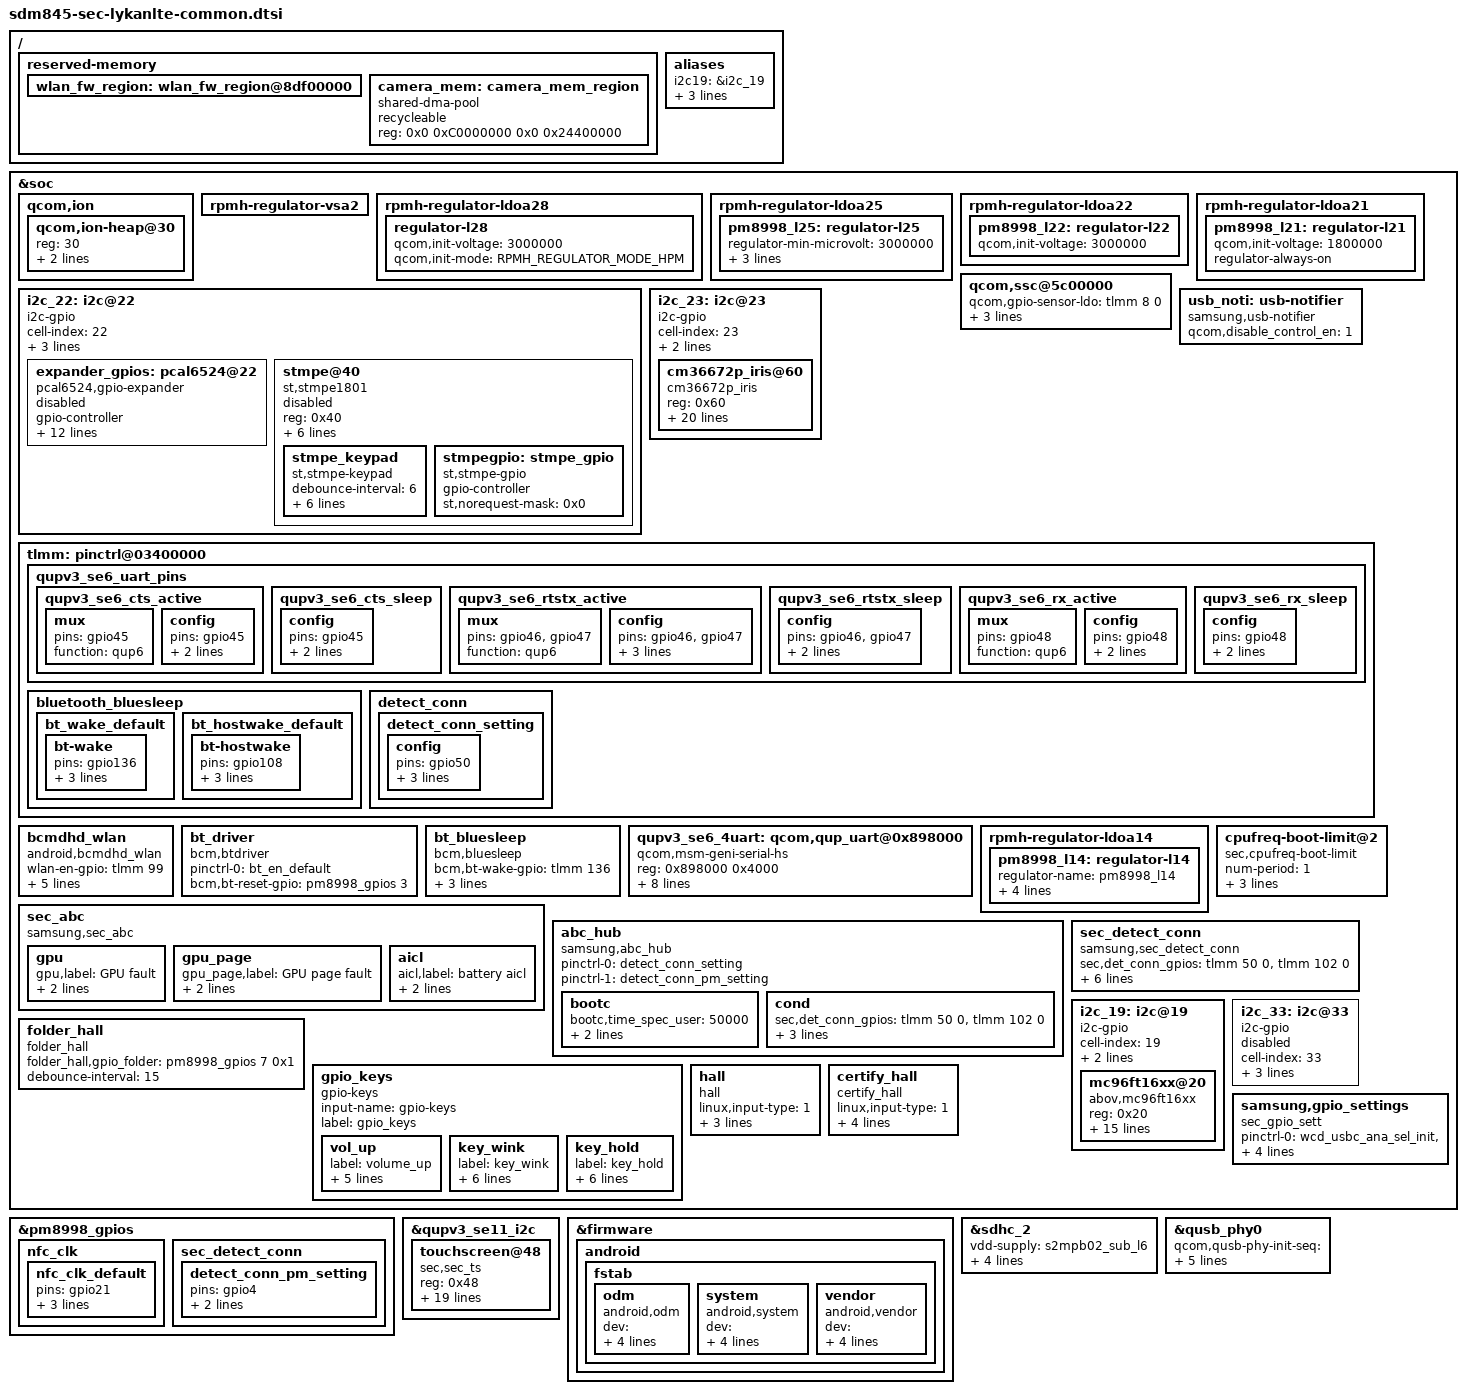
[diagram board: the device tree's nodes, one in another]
/* Copyright (c) 2016-2017, The Linux Foundation. All rights reserved.
 *
 * This program is free software; you can redistribute it and/or modify
 * it under the terms of the GNU General Public License version 2 and
 * only version 2 as published by the Free Software Foundation.
 *
 * This program is distributed in the hope that it will be useful,
 * but WITHOUT ANY WARRANTY; without even the implied warranty of
 * MERCHANTABILITY or FITNESS FOR A PARTICULAR PURPOSE.  See the
 * GNU General Public License for more details.
 */

#include "sdm845-sec-lykan-audio.dtsi"
#include "../../../../drivers/motor/tuning/star2qlte_motor_tuning.dtsi"
#include "../../../../drivers/leds/tuning/star2qlte_led_tuning.dtsi"
#include <dt-bindings/input/input.h>

/{
	reserved-memory {
		/*
		 * We need this region only if we use Qualcomm WiFi solution,
		 * otherwise no need.
		 */
		wlan_fw_region: wlan_fw_region@8df00000 {
			/delete-property/ reg;
		};

		camera_mem: camera_mem_region {
			compatible = "shared-dma-pool";
			recycleable;
			reg = <0x0 0xC0000000 0x0 0x24400000>;
		};
	};

	aliases {
		i2c19 = &i2c_19;
		i2c22 = &i2c_22;
		i2c33 = &i2c_33;
		spi2 = &qupv3_se2_spi;
	};

};

&soc {
	qcom,ion {
		qcom,ion-heap@30 { /* CAMERA HEAP  */
			reg = <30>;
			memory-region = <&camera_mem>;
			qcom,ion-heap-type = "RBIN";
		};
	};

	rpmh-regulator-vsa2 {
	};
	rpmh-regulator-ldoa28 {
		regulator-l28 {
			qcom,init-voltage = <3000000>;
			qcom,init-mode = <RPMH_REGULATOR_MODE_HPM>;
		};
	};
	
	rpmh-regulator-ldoa25 {
		pm8998_l25: regulator-l25 {
			regulator-min-microvolt = <3000000>;
			regulator-max-microvolt = <3312000>;
			qcom,init-voltage = <3000000>;
			qcom,init-mode = <RPMH_REGULATOR_MODE_LPM>;
			/delete-property/regulator-always-on;
		};
	};

	rpmh-regulator-ldoa22 {
		pm8998_l22: regulator-l22 {
			qcom,init-voltage = <3000000>;
		};
	};

	rpmh-regulator-ldoa21 {
		pm8998_l21: regulator-l21 {
			qcom,init-voltage = <1800000>;
			regulator-always-on;
		};
	};

	/* sensor ldo control gpio */
	qcom,ssc@5c00000 {
		/* GPIO control sensor LDO */
		qcom,gpio-sensor-ldo = <&tlmm 8 0>;
		pinctrl-names = "default", "sleep", "idle";
		pinctrl-0 = <&sensor_ldo_default>;
		pinctrl-1 = <&sensor_ldo_active>;
		pinctrl-2 = <&sensor_ldo_active>;
	};

	i2c_22: i2c@22 { /* pcal6524*/
		cell-index = <22>;
		compatible = "i2c-gpio";
		gpios = <&tlmm 123 0 /* sda */
			&tlmm 124 0 /* scl */
		>;
		i2c-gpio,delay-us = <2>;
		#address-cells = <1>;
		#size-cells = <0>;
		pinctrl-names = "default";
		pinctrl-0 = <&i2c_22_active>;

		expander_gpios: pcal6524@22 {
			compatible = "pcal6524,gpio-expander";
			status = "disabled";
			gpio-controller;
			#gpio-cells = <2>;
			reg = <0x22>;
			pinctrl-names = "expander_reset_setting";
			pinctrl-0 = <&expander_reset_active>;
			pcal6524,gpio_start = <300>;
			pcal6524,ngpio = <24>;
			pcal6524,reset-gpio = <&tlmm 69 0>;
			pcal6524,vdd-supply = <&pm8998_s4>;
			pcal6524,support_initialize = <1>;
			/* config, 24 ~ 0, 1bit configure[1:input, 0:output]*/
			pcal6524,config = <0x7FFFFF>;    /* P2[01111111] P1[11111111] P0[11111111] */
			/* data_out, 24 ~ 0, 1bit configure[1:high, 0:low]*/
			pcal6524,data_out = <0x000000>;  /* P2[00000000] P1[00000000] P0[00000000] */
			/* pull_reg, 8 ~ 0, 2bit configure[00:no_pull, 01:pull_down, 10:pull_up, 11:not used] */
			pcal6524,pull_reg_p0 = <0x0000>; /* 00 00 00 00 / 00 00 00 00 */
			pcal6524,pull_reg_p1 = <0x0000>; /* 00 00 00 00 / 00 00 00 00 */
			pcal6524,pull_reg_p2 = <0x0000>; /* 00 00 00 00 / 00 00 00 00 */
		};

		stmpe@40 {
			compatible = "st,stmpe1801";
			status = "disabled";
			reg = <0x40>;
			interrupt-parent = <&tlmm>;
			interrupts = <145 0>;
			irq-gpio = <&tlmm 145 0x08>;
			reset-gpio = <&tlmm 69 0x00>;
			vcc-supply = <&pm8998_s4>;
			//reset-supply = <&stmpe_reset>;
			ledvddo-supply = <&pm8998_l22>; 
								
			stmpe_keypad {
				compatible = "st,stmpe-keypad";

				debounce-interval = <6>;
				st,scan-count = <2>;
				st,no-autorepeat;
				keypad,num-rows = <5>;
				keypad,num-columns = <5>;	//  row   colume   keycode
				linux,keymap = <0x000000e7	/* KEY_SEND KEYCODE = 231 */
						0x0001000e	/* KEY_BACKSPACE 14 */
						0x00020224	/* KEY_NETWORK_SEL 548*/
						0x000300ac	/* KEY_HOMEPAGE 172*/
						0x00040161	/* KEY_ENTER 353 */

						0x01000002	/* KEY_1 2 */
						0x01010003	/* KEY_2 3 */
						0x01020004	/* KEY_3 4 */
						0x01030069	/* KEY_LEFT 105 */
						0x0104006c	/* KEY_DOWN 108 */

						0x02000005	/* KEY_4 5 */
						0x02010006	/* KEY_5 6 */
						0x02020007	/* KEY_6 7 */
						0x0203009e	/* KEY_BACK 158 */
						0x0204006a	/* KEY_RIGHT 106 */

						0x03000008	/* KEY_7 8 */
						0x03010009	/* KEY_8 9 */
						0x0302000a	/* KEY_9 10 */
						0x03030067	/* KEY_UP 103 */

						0x0400020a	/* KEY_NUMERIC_STAR 0x20a */
						0x0401000b	/* KEY_0 11 */
						0x0402020b	/* KEY_NUMERIC_POUND 0x20b */
						0x040300fe>;	/* KEY_RECENT 254 */				
				};

				stmpegpio:stmpe_gpio {
					compatible = "st,stmpe-gpio";
					gpio-controller;
					#gpio-cells = <2>;
					st,norequest-mask = <0x0>;
			};
		};
	};

	i2c_23: i2c@23 { /* SW I2C */
	        cell-index = <23>;
	        compatible = "i2c-gpio";
	        gpios = <&tlmm 91 0 /* sda */
	        	&tlmm 92 0 /* scl */
	        >;
	        i2c-gpio,delay-us = <2>;
	        #address-cells = <1>;
	        #size-cells = <0>;

	        cm36672p_iris@60 {
	            compatible = "cm36672p_iris";
	            reg = <0x60>;
	            pinctrl-names = "default", "sleep";
	            pinctrl-0 = <&cm36672p_int_active &cm36672p_i2c_active>;
	            pinctrl-1 = <&cm36672p_int_suspend &cm36672p_i2c_suspend>;
	            interrupt-parent = <&tlmm>;
	            interrupts = <122 0>;
	            cm36672p_iris,irq_gpio = <&tlmm 122 0x1>;
	            cm36672p_iris,vio-supply = <&pm8998_l21>;
	            cm36672p_iris,vdd-supply = <&s2mpb02_l16>;
	            cm36672p_iris,vled-supply = <&s2mpb02_l18>;
	            cm36672p_iris,default_hi_thd = <22>;
	            cm36672p_iris,default_low_thd = <2>;
	            cm36672p_iris,cancel_hi_thd = <8>;
	            cm36672p_iris,cancel_low_thd = <5>;
	            cm36672p_iris,default_trim = <20>;
	            cm36672p_iris,ps_duty = <2>;
	            cm36672p_iris,ps_pers = <2>;
	            cm36672p_iris,ps_it = <6>;
	            cm36672p_iris,led_current = <2>;
	            cm36672p_iris,ps_smart_pers = <1>;
		};
	};

	usb_noti: usb-notifier {
		compatible = "samsung,usb-notifier";
		qcom,disable_control_en = <1>;
	};
	tlmm: pinctrl@03400000 {
		/delete-node/ qupv3_se6_4uart_pins;
		qupv3_se6_uart_pins: qupv3_se6_uart_pins {
			qupv3_se6_cts_active: qupv3_se6_cts_active {
				mux {
					pins = "gpio45";
					function = "qup6";
				};
				config {
					pins = "gpio45";
					drive-strength = <2>;
					bias-pull-up;
				};
			};

			qupv3_se6_cts_sleep: qupv3_se6_cts_sleep {
				config {
					pins = "gpio45";
					drive-strength = <2>;
					bias-pull-up;
				};
			};

			qupv3_se6_rtstx_active: qupv3_se6_rtstx_active {
				mux {
					pins = "gpio46", "gpio47";
					function = "qup6";
				};
				config {
					pins = "gpio46","gpio47";
					drive-strength = <2>;
					output-high;
					bias-pull-up;
				};
			};

			qupv3_se6_rtstx_sleep: qupv3_se6_rtstx_sleep {
				config {
					pins = "gpio46","gpio47";
					drive-strength = <2>;
					bias-pull-up;
				};
			};

			qupv3_se6_rx_active: qupv3_se6_rx_active {
				mux {
					pins = "gpio48";
					function = "qup6";
				};
				config {
					pins = "gpio48";
					drive-strength = <2>;
					bias-pull-up;
				};
			};

			qupv3_se6_rx_sleep: qupv3_se6_rx_sleep {
				config {
					pins = "gpio48";
					drive-strength = <2>;
					bias-pull-up;
				};
			};
		};

		bluetooth_bluesleep {
			bt_wake_default: bt_wake_default {
				bt-wake {
					pins = "gpio136";
					function = "gpio";
					drive-strength = <2>;
					bias-pull-down;
				};
			};
			bt_hostwake_default: bt_hostwake_default {
				bt-hostwake {
					pins = "gpio108";
					function = "gpio";
					drive-strength = <2>;
					bias-pull-down;
				};
			};
		};
	};

	bcmdhd_wlan {
		compatible = "android,bcmdhd_wlan";
		wlan-en-gpio = <&tlmm 99 0>;
		wlan-host-wake-gpio = <&tlmm 116 0>;
		wlan-smmu-iova-address = <0xa0000000 0x10000000>;
		pinctrl-name = "bcmdhd_wlan_en","bcmdhd_default";
		pinctrl-0 = <&bcmdhd_wlan_en>;
		pinctrl-1 = <&bcmdhd_default>;
		status = "ok";
	};

	bt_driver {
		compatible = "bcm,btdriver";  //bt_en
		pinctrl-names = "default";
		pinctrl-0 = <&bt_en_default>;
		bcm,bt-reset-gpio = <&pm8998_gpios 3 GPIO_ACTIVE_HIGH>;
		status = "okay";
	};

	bt_bluesleep {
		compatible = "bcm,bluesleep";
		bcm,bt-wake-gpio = <&tlmm 136 0>;
		bcm,bt-host-wake-gpio = <&tlmm 108 0>;
		pinctrl-names = "default";
		pinctrl-0 = <&bt_wake_default &bt_hostwake_default>;
		status = "okay";
	};

	qupv3_se6_4uart: qcom,qup_uart@0x898000 {
		compatible = "qcom,msm-geni-serial-hs", "qcom,msm-geni-uart";
		reg = <0x898000 0x4000>;
		reg-names = "se_phys";
		clock-names = "se-clk", "m-ahb", "s-ahb";
		clocks = <&clock_gcc GCC_QUPV3_WRAP0_S6_CLK>,
			<&clock_gcc GCC_QUPV3_WRAP_0_M_AHB_CLK>,
			<&clock_gcc GCC_QUPV3_WRAP_0_S_AHB_CLK>;
		pinctrl-names = "default", "sleep";
		pinctrl-0 = <&qupv3_se6_cts_active &qupv3_se6_rtstx_active &qupv3_se6_rx_active>;
		pinctrl-1 = <&qupv3_se6_cts_sleep &qupv3_se6_rtstx_sleep &qupv3_se6_rx_sleep>;
		interrupts-extended = <&pdc GIC_SPI 607 0>;
		status = "okay";
	};

	rpmh-regulator-ldoa14 {
		pm8998_l14: regulator-l14 {
			regulator-name = "pm8998_l14";
			regulator-min-microvolt = <1800000>;
			regulator-max-microvolt = <1880000>;
			qcom,init-voltage = <1800000>;
			qcom,init-mode = <RPMH_REGULATOR_MODE_LPM>;
		};
	};

	cpufreq-boot-limit@2 {
		compatible = "sec,cpufreq-boot-limit";
		num-period = <1>;
		limit-temp = <(-70)>;
		limit-freq-table = <0 1536000 40000>;
		limit-for-user-bin;
		status = "ok";
	};

	sec_abc {
		compatible = "samsung,sec_abc";
		status = "okay";

		gpu {
			gpu,label="GPU fault";
			gpu,threshold_count=<4>;
			gpu,threshold_time=<1200>;
		};
		gpu_page {
			gpu_page,label="GPU page fault";
			gpu_page,threshold_count=<20>;
			gpu_page,threshold_time=<1200>;
		};
		aicl {
			aicl,label="battery aicl";
			aicl,threshold_count=<5>;
			aicl,threshold_time=<300>;
		};
	};

	abc_hub {
		compatible = "samsung,abc_hub";
		status = "okay";
		pinctrl-names = "det_ap_connect", "det_pm_connect";
		pinctrl-0 = <&detect_conn_setting>;
		pinctrl-1 = <&detect_conn_pm_setting>;
		
		bootc {
			bootc,time_spec_user = <50000>; /* user binary user build */
			bootc,time_spec_eng = <90000>; /* user binary eng build */
			bootc,time_spec_fac = <40000>; /* factory binary */
		};


		cond {
			sec,det_conn_gpios = <&tlmm 50 0 /* UB_CON_DETECT */
				&tlmm 102 0>; /* SUB_DETECT */
			
			sec,det_conn_name = "ub", "sub";
			sec,det_pm_conn_gpios = <&pm8998_gpios 4 0x1>; /* CAM_DETECT */
			sec,det_pm_conn_name = "cam";
		};
	};
	
	tlmm: pinctrl@03400000 {
		detect_conn {
			detect_conn_setting: detect_conn_setting {
				config {
					pins = "gpio50";
					drive-strength = <2>;
					bias-disable; /* No PULL */
					input-enable;
				};
			};
		};
	};
	
	sec_detect_conn {
		compatible = "samsung,sec_detect_conn";
		sec,det_conn_gpios = <&tlmm 50 0 /* UB_CON_DETECT */
					&tlmm 102 0>; /* SUB_DETECT */

		sec,det_conn_name = "UB_CONNECT", "SUB_CONNECT";

		sec,det_conn_irq_type = <3>, /* UB_CON_DETECT FALLING, RIGING EDGE*/
					<3>; /* SUB_DETECT FALLING, RIGING EDGE*/

		sec,det_pm_conn_gpios = <&pm8998_gpios 4 0x1>; /* CAM_DETECT */
		sec,det_pm_conn_name = "CAM_CONNECT";
		pinctrl-names = "det_ap_connect", "det_pm_connect";
		pinctrl-0 = <&detect_conn_setting>;
		pinctrl-1 = <&detect_conn_pm_setting>;
	};

	i2c_19: i2c@19 { /* SW I2C */
		cell-index = <19>;
		compatible = "i2c-gpio";
		gpios = <&tlmm 114 0 /* sda */
				&tlmm 115 0 /* scl */
		>;
		#i2c-gpio,delay-us = <2>;
		#address-cells = <1>;
		#size-cells = <0>;
		
		mc96ft16xx@20{
			compatible = "abov,mc96ft16xx";
			reg = <0x20>;
			interrupt-parent = <&tlmm>;
			interrupts = <79 0>;
			pinctrl-names = "touchkey_active", "touchkey_suspend";
			pinctrl-0 = <&touchkey_i2c_active &touchkey_int_active>;
			pinctrl-1 = <&touchkey_i2c_suspend &touchkey_int_suspend>;
			abov,avdd-supply = <&s2mpb02_sub_l17>;
			abov,vddo-supply = <&pm8998_s4>;
			abov,ledavdd-supply = <&s2mpb02_sub_l16>;
			abov,sda-gpio = <&tlmm 114 0x0>;
			abov,scl-gpio = <&tlmm 115 0x0>;
			abov,irq-gpio = <&tlmm 79 0x0>;
			abov,hall_flip-gpio = <&tlmm 96 0>;
			abov,reg-boot-on; /* enable supply when pmic boot on */
			abov,fw-name = "abov/abov_tk_kelly.fw";
		};
	};

	folder_hall {
		compatible = "folder_hall";
		folder_hall,gpio_folder = <&pm8998_gpios 7 0x1>;
		debounce-interval = <15>;
	};

	i2c_33: i2c@33 {
		cell-index = <33>;
		compatible = "i2c-gpio";
		gpios = <&tlmm 103 0 /* sda */
			&tlmm 104 0 /* scl */
		>;
		#address-cells = <1>;
		#size-cells = <0>;		
		i2c-gpio,delay-us = <2>;
		pinctrl-names = "default";
		pinctrl-0 = <&i2c_33_active>;
		status = "disabled";
	};
};

/delete-node/&slim_qca;

&pm8998_gpios {
	/delete-node/ key_home;
	/delete-node/ key_vol_up;

	nfc_clk {
		nfc_clk_default: nfc_clk_default {
			pins = "gpio21";
			function = "normal";
			input-enable;
			power-source = <1>;
		};
	};
	
	sec_detect_conn {
		detect_conn_pm_setting: detect_conn_pm_setting {
			pins = "gpio4";
			bias-disable; /* No PULL */
			input-enable;
		};
	};
};

&qupv3_se11_i2c {
	status = "ok";

	touchscreen@48 {
		compatible = "sec,sec_ts";
		reg = <0x48>;
		interrupt-parent = <&tlmm>;
		interrupts = <120 0>;

		status = "okay";
		pinctrl-names = "on_state", "off_state";
		pinctrl-0 = <&attn_irq &tsp_sel_gpio>;
		pinctrl-1 = <&attn_irq &tsp_sel_gpio>;
		sec,tsp_sel = <&tlmm 96 0>;
		sec,regulator_dvdd = "s2mpb02-sub-ldo9";
		sec,regulator_avdd = "s2mpb02-sub-ldo14";
		sec,regulator_boot_on;
		sec,irq_gpio = <&tlmm 120 0x2008>;
		sec,irq_type = <0x2008>;
		sec,max_coords = <4096 4096>;   /* x y */
		sec,mis_cal_check = <1>;
		sec,afe_base = <0x0108>;
		sec,tclm_level = <2>;
		sec,project_name = "LYKAN", "2019";
		sec,bringup = <0>;
		sec,firmware_name = "tsp_sec/y661_lykan.fw";
		sec,i2c-burstmax = <0x40>;
		sec,factory_item_version = <2>;
	};
};

&soc {
	/delete-node/ gpio_keys;
	gpio_keys {
		compatible = "gpio-keys";
		input-name = "gpio-keys";
		status = "okay";
		label = "gpio_keys";

		vol_up {
			label = "volume_up";
			gpios = <&pm8998_gpios 6 GPIO_ACTIVE_LOW>;
			linux,input-type = <1>;
			linux,code = <KEY_VOLUMEUP>;
			debounce-interval = <15>;
			linux,can-disable;
		};

		key_wink {
			label = "key_wink";
			gpios = <&pm8998_gpios 19 GPIO_ACTIVE_LOW>;
			linux,input-type = <1>;
			linux,code = <KEY_WINK>;
			gpio-key,wakeup;
			debounce-interval = <15>;
			linux,can-disable;
		};

		key_hold {
			label = "key_hold";
			gpios = <&pm8998_gpios 15 GPIO_ACTIVE_LOW>;
			linux,input-type = <1>;
			linux,code = <KEY_POWER>;
			gpio-key,wakeup;
			debounce-interval = <15>;
			linux,can-disable;
		};
	};

	hall {
		status = "okay";
		compatible = "hall";
		linux,input-type = <1>;
		linux,code = <21>;
		hall,gpio_flip_cover = <&pm8998_gpios 15 0x1>;
		debounce-interval = <15>;
	};

	certify_hall {
		compatible = "certify_hall";
		linux,input-type = <1>;
		linux,code = <27>;
		certify_hall,gpio_certify_cover = <&pm8998_gpios 7 0x1>;
		debounce-interval = <15>;
	};

	samsung,gpio_settings{
		compatible = "sec_gpio_sett";
		pinctrl-names = "sec_gpio_init","sec_gpio_active","sec_gpio_suspend";
		pinctrl-0 = <&wcd_usbc_ana_sel_init &wcd_usbc_en_init>;
		pinctrl-1 = <&nc_config_active &keypad_int_active>;
		pinctrl-2 = <&nc_config_suspend &keypad_int_suspend>;
	};
};

&firmware {
	android {
		fstab {
			odm {
				compatible = "android,odm";
				/* dev = "/dev/block/bootdevice/by-name/odm"; */
				dev = "/dev/block/platform/soc/1d84000.ufshc/by-name/odm";
				type = "ext4";
				mnt_flags = "ro,errors=panic";
				fsmgr_flags = "wait";
			};
			system {
				compatible = "android,system";
				/* dev = "/dev/block/bootdevice/by-name/system"; */
				dev = "/dev/block/platform/soc/1d84000.ufshc/by-name/system";
				type = "ext4";
				mnt_flags = "ro,errors=panic";
				fsmgr_flags = "wait";
			};
			vendor {
				compatible = "android,vendor";
				/* dev = "/dev/block/bootdevice/by-name/vendor"; */
				dev = "/dev/block/platform/soc/1d84000.ufshc/by-name/vendor";
				type = "ext4";
				mnt_flags = "ro,barrier=1,discard";
				fsmgr_flags = "wait";
			};
		};
	};
};

&sdhc_2 {
	vdd-supply = <&s2mpb02_sub_l6>;
	qcom,vdd-voltage-level = <2950000 2950000>;
	qcom,vdd-current-level = <200 800000>;
	pinctrl-names = "active", "sleep", "default";
	sec,tflash-en-gpio = <&expander_gpios 0 0>;     /* GPIO Expander P0_0 */
	pinctrl-2 = <&sdc2_sim_det_default>;
};

&qusb_phy0 {
	qcom,qusb-phy-init-seq =
	/* <value reg_offset> */
		<0x23 0x210 /* PWR_CTRL1 */
		 0x03 0x04	/* PLL_ANALOG_CONTROLS_TWO */
		 0x7c 0x18c /* PLL_CLOCK_INVERTERS */
		 0x80 0x2c	/* PLL_CMODE */
		 0x0a 0x184 /* PLL_LOCK_DELAY */
		 0x19 0xb4	/* PLL_DIGITAL_TIMERS_TWO */
		 0x40 0x194 /* PLL_BIAS_CONTROL_1 */
		 0x1b 0x198 /* PLL_BIAS_CONTROL_2 */
		 0x21 0x214 /* PWR_CTRL2 */
		 0x0e 0x220 /* IMP_CTRL1 */
		 0x58 0x224 /* IMP_CTRL2 */
		 0x75 0x240 /* TUNE1 */
		 0x29 0x244 /* TUNE2 */
		 0xca 0x248 /* TUNE3 */
		 0x02 0x24c /* TUNE4 */
		 0x03 0x250 /* TUNE5 */
		 0x00 0x23c /* CHG_CTRL2 */
		 0x22 0x210>; /* PWR_CTRL1 */

	qcom,qusb-phy-host-init-seq =
	/* <value reg_offset> */
		<0x23 0x210 /* PWR_CTRL1 */
		 0x03 0x04	/* PLL_ANALOG_CONTROLS_TWO */
		 0x7c 0x18c /* PLL_CLOCK_INVERTERS */
		 0x80 0x2c	/* PLL_CMODE */
		 0x0a 0x184 /* PLL_LOCK_DELAY */
		 0x19 0xb4	/* PLL_DIGITAL_TIMERS_TWO */
		 0x40 0x194 /* PLL_BIAS_CONTROL_1 */
		 0x20 0x198 /* PLL_BIAS_CONTROL_2 */
		 0x21 0x214 /* PWR_CTRL2 */
		 0x0e 0x220 /* IMP_CTRL1 */
		 0x58 0x224 /* IMP_CTRL2 */
		 0x32 0x240 /* TUNE1 */
		 0x29 0x244 /* TUNE2 */
		 0xca 0x248 /* TUNE3 */
		 0x02 0x24c /* TUNE4 */
		 0x03 0x250 /* TUNE5 */
		 0x00 0x23c /* CHG_CTRL2 */
		 0x22 0x210>; /* PWR_CTRL1 */

	qcom,diff_tune_host = <(0)>; /* efuse(0x3) + 4 = 7 for tune high value */
	qcom,diff_tune_device = <(4)>;
};
